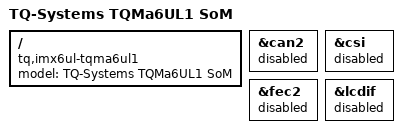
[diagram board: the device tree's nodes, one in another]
// SPDX-License-Identifier: (GPL-2.0-or-later OR MIT)
/*
 * Copyright 2018-2022 TQ-Systems GmbH
 * Author: Markus Niebel <Markus.Niebel@tq-group.com>
 */

/ {
	model = "TQ-Systems TQMa6UL1 SoM";
	compatible = "tq,imx6ul-tqma6ul1", "fsl,imx6ul";
};

/*
 * There are no module specific differences compared to TQMa6UL2,
 * only external interfaces differ
 */

/*
 * Devices not available on i.MX6ULG1 and should not be enabled on
 * mainboard level (again)
 */
&can2 {
	status = "disabled";
};

&csi {
	status = "disabled";
};

&fec2 {
	status = "disabled";
};

&lcdif {
	status = "disabled";
};
